# RasbperryPi register map
File version: 1
Registers are 32-bit, read-write, reset 0x0 unless marked. A register's access mark holds for its fields unless they carry their own. Offsets are from the block's base; [hi:lo] are bit positions; {n}, {i} and the like mark numbered series; 'fields as' and 'values as' point back to an identical list.

## TE — Derived from tectl_a0.h apb_id: 0x00746563
Base 0x7E20E000
{0x0+8i} {i}C reset not defined (i=0..2)
  [31:0] data
{0x4+8i} {i}VSWIDTH reset not defined (i=0..2)
  [31:0] data

## TS — Derived from tempsens.h apb_id: 0x7473656E
Base 0x7E212000
0x00 TSENSCTL 27-bit
  [26] REGULEN, [25:18] RSTDELAY, [17:8] THOLD, [7] CLR_INT, [6] DIRECT, [5] EN_INT, [4:2] CTRL, [1] RSTB, [0] PRWDW
0x04 TSENSSTAT 12-bit
  [11] INTERUPT, [10] VALID, [9:0] DATA

## TB — Derived from testbus.h
Base 0x7E20B000
0x00 ADDR reset not defined
  [31:0] data
0x00 TASK 17-bit reset not defined
  [16] TEXT_FLAG, [15:0] NUM
0x00 HDMI reset not defined
  [31:0] data
0x00 PCM reset not defined
  [31:0] data
0x00 HOST reset not defined
  [31:0] data
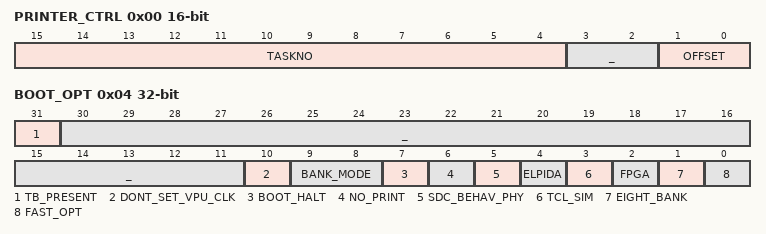
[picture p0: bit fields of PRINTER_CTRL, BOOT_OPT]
0x00 PRINTER_CTRL 16-bit reset not defined
  [15:4] TASKNO, [3:2] _, [1:0] OFFSET
0x00 BOOT_ADDR reset not defined
  [31:0] data
0x00 JTB_CONFIG reset not defined
  [31] BUSY, [30] _, [29:23] BITCNT, [23:16] SPEED, [15] _, [14] TRSTN, [13:12] D_HOLD, [11] ENABLE, [10] TDO_RISE, [9] TDI_RISE, [8] TMS_RISE, [7] INV_CLK, [6] OUT_MS, [5] _, [4:0] SBITS
0x04 PRINTER_DATA reset not defined
0x04 BOOT_OPT reset not defined
  [31] TB_PRESENT, [30:11] _, [10] DONT_SET_VPU_CLK, [9:8] BANK_MODE, [7] BOOT_HALT, [6] NO_PRINT, [5] SDC_BEHAV_PHY, [4] ELPIDA, [3] TCL_SIM, [2] FPGA, [1] EIGHT_BANK, [0] FAST_OPT
0x04 JTB_TMS reset not defined
  [31:0] data
0x08 BOOT_SECURE_MODE 2-bit reset not defined
  [1:0] JTAG_SECURE
0x08 JTB_TDI reset not defined
  [31:0] data
0x0C BOOT_STATUS 1-bit reset not defined
  [0] CPRMAN_PROGRAMMED
0x0C JTB_TDO ro reset not defined
  [31:0] data
0x10 JTB_BITCNT 6-bit reset not defined
  [5:0] data
0x14 JTB_PORTEN 8-bit reset not defined
  [7:0] data

## TH — Derived from thread_ctrl.h apb_id: 0x74687265
Base 0x18E00000
0x00 XCS
  [31:0] data

## TXP — Derived from txp.h apb_id: 0x20763374
Base 0x7E004000
0x00 DST_PTR reset not defined
  [31:0] data
0x04 DST_PITCH reset not defined
  [31:0] data
0x08 DIM 28-bit reset not defined
  [27:16] HEIGHT, [15:12] _, [11:0] WIDTH
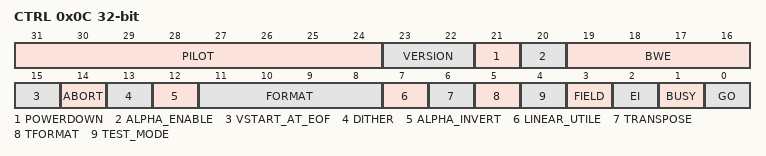
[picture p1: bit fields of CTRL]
0x0C CTRL reset not defined
  [31:24] PILOT, [23:22] VERSION, [21] POWERDOWN, [20] ALPHA_ENABLE, [19:16] BWE, [15] VSTART_AT_EOF, [14] ABORT, [13] DITHER, [12] ALPHA_INVERT, [11:8] FORMAT, [7] LINEAR_UTILE, [6] TRANSPOSE, [5] TFORMAT, [4] TEST_MODE, [3] FIELD, [2] EI, [1] BUSY, [0] GO
0x10 PROGRESS 12-bit ro reset not defined
  [11:0] LINES
0x18 XTRA 1-bit reset not defined
  [0] NOSTBY

## UART — Derived from uart.h
Base 0x7E201000
0x00 RBRTHRDLL reset not defined
  [31:0] data

## VEC — Derived from vec.h
Base 0x7E806000
0x00 REVID reset not defined
  [31:0] data
0x00 STATUS0 reset not defined
  [31:0] data
0x04 CONFIG0 reset not defined
  [31:0] data
0x04 MASK0 reset not defined
  [31:0] data
0x08 SCHPH reset not defined
  [31:0] data
0x08 CFG reset not defined
  [31:0] data
0x0C SOFT_RESET reset not defined
  [31:0] data
0x0C DAC_TEST reset not defined
  [31:0] data
0x10 DAC_CONFIG reset not defined
  [31:0] data
0x14 DAC_MISC reset not defined
  [31:0] data
0x20 CPS01_CPS23 reset not defined
  [31:0] data
0x24 CPS45_CPS67 reset not defined
  [31:0] data
0x28 CPS89_CPS1011 reset not defined
  [31:0] data
0x2C CPS1213_CPS1415 reset not defined
  [31:0] data
0x30 CPS1617_CPS1819 reset not defined
  [31:0] data
0x34 CPS2021_CPS2223 reset not defined
  [31:0] data
0x38 CPS2425_CPS2627 reset not defined
  [31:0] data
0x3C CPS2829_CPS3031 reset not defined
  [31:0] data
0x40 CPS32_CPC reset not defined
  [31:0] data
0x40 CGMSAE_RESET reset not defined
  [31:0] data
0x44 CLMP0_START reset not defined
  [31:0] data
0x44 CGMSAE_TOP_CONTROL reset not defined
  [31:0] data
0x48 CLMP0_END reset not defined
  [31:0] data
0x48 CGMSAE_BOT_CONTROL reset not defined
  [31:0] data
0x4C CGMSAE_TOP_FORMAT reset not defined
  [31:0] data
0x50 CGMSAE_BOT_FORMAT reset not defined
  [31:0] data
0x54 CGMSAE_TOP_DATA reset not defined
0x58 CGMSAE_BOT_DATA reset not defined
0x5C CGMSAE_REVID reset not defined
  [31:0] data
0x60 ENC_RevID reset not defined
  [31:0] data
0x68 ENC_PrimaryControl reset not defined
  [31:0] data
0x80 FREQ3_2 reset not defined
  [31:0] data
0x84 FREQ1_0 reset not defined
  [31:0] data
0x88 CONFIG1 reset not defined
  [31:0] data
0x8C CONFIG2 reset not defined
  [31:0] data
0x90 INTERRUPT_CONTROL reset not defined
  [31:0] data
0x94 INTERRUPT_STATUS reset not defined
  [31:0] data
0x98 FCW_SECAM_B reset not defined
  [31:0] data
0x9C SECAM_GAIN_VAL reset not defined
  [31:0] data
0xA0 CONFIG3 reset not defined
  [31:0] data
0xA4 CONFIG4 reset not defined
  [31:0] data
0xC0 WSE_RESET reset not defined
  [31:0] data
0xC4 WSE_CONTROL reset not defined
  [31:0] data
0xC8 WSE_WSS_DATA reset not defined
0xCC WSE_VPS_DATA_1 reset not defined
  [31:0] data
0xD0 WSE_VPS_CONTROL reset not defined
  [31:0] data

## VPU_ARB_CTRL — Derived from vpu_arb_ctrl.h
Base 0x7EE04000
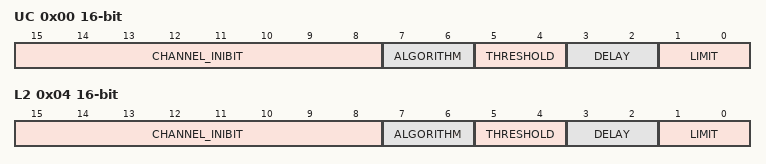
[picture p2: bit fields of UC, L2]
0x00 UC 16-bit
  [15:8] CHANNEL_INIBIT, [7:6] ALGORITHM, [5:4] THRESHOLD, [3:2] DELAY, [1:0] LIMIT
0x04 L2 16-bit
  fields as UC

## L1 — Derived from vpu_l1_cache_ctrl.h apb_id: 0x4C314343
Base 0x7EE02000
0x00 IC0_CONTROL 7-bit
  [6:5] DISABLE_VLINE, [4] RAS_DISABLE, [3] BP_DISABLE, [2] ENABLE_STATS, [1] START_FLUSH, [0] DISABLE
0x00 D_CONTROL 4-bit
  [3] DC_EN_STATS, [2] DC1_FLUSH, [1] DC0_FLUSH, [0] DC_DISABLE
0x00 L1_SANDBOX_START0 30-bit reset 0x7
  [29:5] START_ADDR, [4:1] _, [0] CTRL
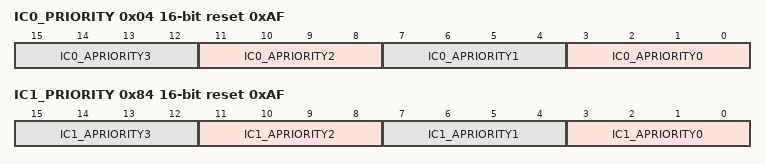
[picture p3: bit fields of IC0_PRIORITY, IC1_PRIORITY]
0x04 IC0_PRIORITY 16-bit reset 0xAF
  [4n+3:4n] IC0_APRIORITY{n} (n=0..3)
0x04 D_FLUSH_S 30-bit
  [29:0] data
0x04 L1_SANDBOX_END0 30-bit reset 0xE0
  [29:0] data
0x08 IC0_FLUSH_S
  [31:0] data
0x08 D_FLUSH_E 30-bit reset 0xFF
  [29:0] data
{0x0+8i} L1_SANDBOX_START{i} 30-bit (i=1..7)
  [29:5] START_ADDR, [4:1] _, [0] CTRL
0x0C IC0_FLUSH_E reset 0xFF
  [31:0] data
0x0C D_PRIORITY 28-bit
  [27:24] c1_per_priority, [23:20] c1_uc_priority, [19:16] c1_l2_priority, [15:12] _, [11:8] c0_per_priority, [7:4] c0_uc_priority, [3:0] c0_l2_priority
{0x4+8i} L1_SANDBOX_END{i} 30-bit (i=1..7)
  [29:0] data
0x40 IC0_RD_HITS size not given reset not defined
0x40 D0_RD_HITS size not given reset not defined
0x40 L1_SANDBOX_PERI_BR 13-bit reset 0x7
  [12:8] sandbox_peri, [7:5] _, [4:0] sandbox_bootrom
0x44 IC0_RD_MISSES size not given ro reset not defined
0x44 D0_RD_SNOOPS size not given ro reset not defined
0x48 IC0_BP_HITS size not given ro reset not defined
0x48 D0_RD_MISSES size not given ro reset not defined
0x4C IC0_BP_MISSES size not given ro reset not defined
0x4C D0_RD_THRUS size not given ro reset not defined
0x50 IC0_RAS_PUSHES size not given ro reset not defined
0x50 D0_WR_HITS size not given ro reset not defined
0x54 IC0_RAS_POPS size not given ro reset not defined
0x54 D0_WR_SNOOPS size not given ro reset not defined
0x58 IC0_RAS_UNDERFLOW size not given ro reset not defined
0x58 D0_WR_MISSES size not given ro reset not defined
0x5C D0_WR_THRUS size not given ro reset not defined
0x60 D0_WBACKS size not given ro reset not defined
0x80 IC1_CONTROL 7-bit
  fields as IC0_CONTROL
0x80 D1_RD_HITS size not given reset not defined
0x84 IC1_PRIORITY 16-bit reset 0xAF
  [4n+3:4n] IC1_APRIORITY{n} (n=0..3)
0x84 D1_RD_SNOOPS size not given ro reset not defined
0x88 IC1_FLUSH_S
  [31:0] data
0x88 D1_RD_MISSES size not given ro reset not defined
0x8C IC1_FLUSH_E reset 0xFF
  [31:0] data
0x8C D1_RD_THRUS size not given ro reset not defined
0x90 D1_WR_HITS size not given ro reset not defined
0x94 D1_WR_SNOOPS size not given ro reset not defined
0x98 D1_WR_MISSES size not given ro reset not defined
0x9C D1_WR_THRUS size not given ro reset not defined
0xA0 D1_WBACKS size not given ro reset not defined
0xC0 IC1_RD_HITS size not given reset not defined
0xC4 IC1_RD_MISSES size not given ro reset not defined
0xC8 IC1_BP_HITS size not given ro reset not defined
0xCC IC1_BP_MISSES size not given ro reset not defined
0xD0 IC1_RAS_PUSHES size not given ro reset not defined
0xD4 IC1_RAS_POPS size not given ro reset not defined
0xD8 IC1_RAS_UNDERFLOW size not given ro reset not defined
